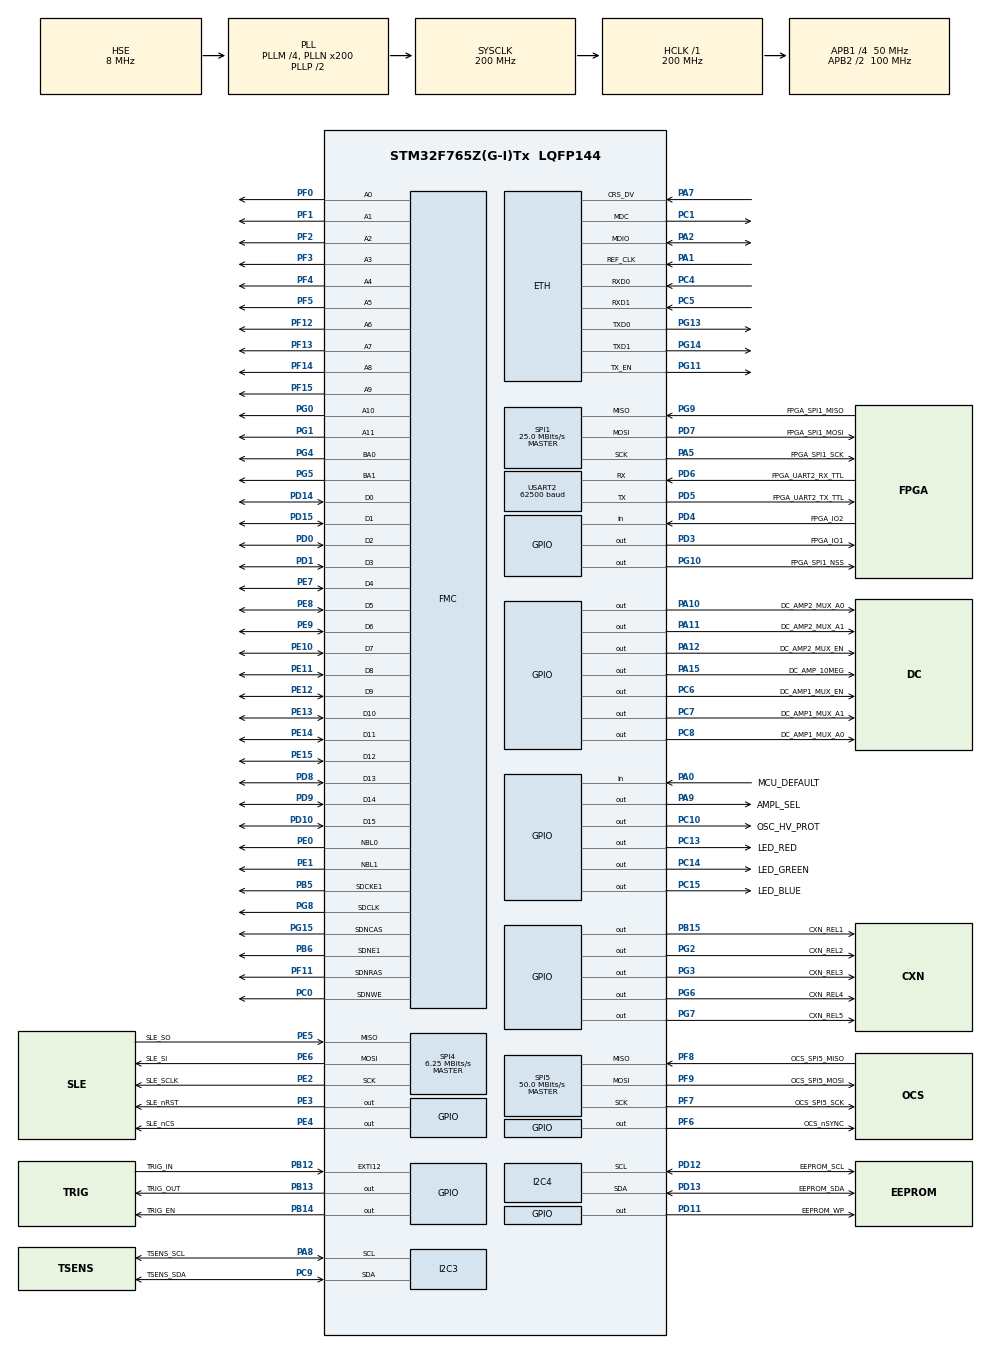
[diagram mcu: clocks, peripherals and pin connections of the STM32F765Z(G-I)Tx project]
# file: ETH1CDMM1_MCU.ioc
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CORTEX_M7.CPU_DCache=Enabled
CORTEX_M7.CPU_ICache=Enabled
ETH.MediaInterface=ETH_MEDIA_INTERFACE_RMII
ETH.PhyAddress=0
FMC.CASLatency1=FMC_SDRAM_CAS_LATENCY_2
FMC.ExitSelfRefreshDelay1=7
FMC.LoadToActiveDelay1=2
FMC.RCDDelay1=2
FMC.RPDelay1=2
FMC.RPDelay2=2
FMC.ReadPipeDelay1=FMC_SDRAM_RPIPE_DELAY_1
FMC.ReadPipeDelay2=FMC_SDRAM_RPIPE_DELAY_1
FMC.RowCycleDelay1=7
FMC.RowCycleDelay2=7
FMC.SDClockPeriod1=FMC_SDRAM_CLOCK_PERIOD_2
FMC.SDClockPeriod2=FMC_SDRAM_CLOCK_PERIOD_2
FMC.SelfRefreshTime1=4
FMC.WriteRecoveryTime1=3
FREERTOS.HEAP_NUMBER=4
FREERTOS.Queues01=QueueTrigger,1,uint8_t,0,Static,QueueTriggerBuffer,QueueTriggerControlBlock
FREERTOS.Tasks01=defaultTask,24,128,StartDefaultTask,Default,NULL,Dynamic,NULL,NULL;LEDTask,8,128,StartLEDTask,Default,NULL,Dynamic,NULL,NULL;TriggerTask,24,128,StartTriggerTask,Default,NULL,Dynamic,NULL,NULL;MeasurTask,25,1024,StartMeasurTask,Default,NULL,Dynamic,NULL,NULL
FREERTOS.configTOTAL_HEAP_SIZE=245760
I2C3.Timing=0x00C0EAFF
I2C4.Timing=0x00C0EAFF
LWIP.CMSIS_VERSION-Enabled=1
LWIP.DEFAULT_THREAD_STACKSIZE=2048
LWIP.GATEWAY_ADDRESS=192.168.000.001
LWIP.IP_ADDRESS=192.168.000.127
LWIP.LWIP_DHCP=0
LWIP.NETMASK_ADDRESS=255.255.255.000
LWIP.SLIPIF_THREAD_STACKSIZE=2048
LWIP.TCPIP_THREAD_STACKSIZE=2048
LWIP.Version=v2.1.2_Cube
Mcu.Family=STM32F7
Mcu.Name=STM32F765Z(G-I)Tx
Mcu.Package=LQFP144
NVIC.ETH_IRQn=true\:5\:0\:false\:false\:true\:true\:false\:true
NVIC.EXTI15_10_IRQn=true\:15\:0\:true\:false\:true\:false\:true\:true
NVIC.PriorityGroup=NVIC_PRIORITYGROUP_4
NVIC.TIM1_UP_TIM10_IRQn=true\:0\:0\:false\:false\:true\:false\:false\:true
NVIC.TimeBase=TIM1_UP_TIM10_IRQn
NVIC.TimeBaseIP=TIM1
PA0/WKUP.GPIO_Label=MCU_DEFAULT
PA0/WKUP.Signal=GPIO_Input
PA1.Mode=RMII
PA1.Signal=ETH_REF_CLK
PA10.GPIO_Label=DC_AMP2_MUX_A0
PA10.Signal=GPIO_Output
PA11.GPIO_Label=DC_AMP2_MUX_A1
PA11.Signal=GPIO_Output
PA12.GPIO_Label=DC_AMP2_MUX_EN
PA12.Signal=GPIO_Output
PA13.Mode=Serial_Wire
PA13.Signal=SYS_JTMS-SWDIO
PA14.Mode=Serial_Wire
PA14.Signal=SYS_JTCK-SWCLK
PA15.GPIO_Label=DC_AMP_10MEG
PA15.Signal=GPIO_Output
PA2.Mode=RMII
PA2.Signal=ETH_MDIO
PA5.GPIO_Label=FPGA_SPI1_SCK
PA5.Mode=Full_Duplex_Master
PA5.Signal=SPI1_SCK
PA7.Mode=RMII
PA7.Signal=ETH_CRS_DV
PA8.GPIO_Label=TSENS_SCL
PA8.Mode=I2C
PA8.Signal=I2C3_SCL
PA9.GPIO_Label=AMPL_SEL
PA9.Signal=GPIO_Output
PB12.GPIO_Label=TRIG_IN
PB12.GPIO_ModeDefaultEXTI=GPIO_MODE_IT_RISING
PB12.Signal=GPXTI12
PB13.GPIO_Label=TRIG_OUT
PB13.Signal=GPIO_Output
PB14.GPIO_Label=TRIG_EN
PB14.PinState=GPIO_PIN_SET
PB14.Signal=GPIO_Output
PB15.GPIO_Label=CXN_REL1
PB15.Signal=GPIO_Output
PB5.Mode=SdramChipSelect2_1
PB5.Signal=FMC_SDCKE1
PB6.Mode=SdramChipSelect2_1
PB6.Signal=FMC_SDNE1
PC0.Signal=FMC_SDNWE
PC1.Mode=RMII
PC1.Signal=ETH_MDC
PC10.GPIO_Label=OSC_HV_PROT
PC10.Signal=GPIO_Output
PC13.GPIO_Label=LED_RED
PC13.PinState=GPIO_PIN_SET
PC13.Signal=GPIO_Output
PC14/OSC32_IN.GPIO_Label=LED_GREEN
PC14/OSC32_IN.PinState=GPIO_PIN_SET
PC14/OSC32_IN.Signal=GPIO_Output
PC15/OSC32_OUT.GPIO_Label=LED_BLUE
PC15/OSC32_OUT.PinState=GPIO_PIN_SET
PC15/OSC32_OUT.Signal=GPIO_Output
PC4.Mode=RMII
PC4.Signal=ETH_RXD0
PC5.Mode=RMII
PC5.Signal=ETH_RXD1
PC6.GPIO_Label=DC_AMP1_MUX_EN
PC6.Signal=GPIO_Output
PC7.GPIO_Label=DC_AMP1_MUX_A1
PC7.Signal=GPIO_Output
PC8.GPIO_Label=DC_AMP1_MUX_A0
PC8.Signal=GPIO_Output
PC9.GPIO_Label=TSENS_SDA
PC9.Mode=I2C
PC9.Signal=I2C3_SDA
PD0.Signal=FMC_D2_DA2
PD1.Signal=FMC_D3_DA3
PD10.Signal=FMC_D15_DA15
PD11.GPIO_Label=EEPROM_WP
PD11.PinState=GPIO_PIN_SET
PD11.Signal=GPIO_Output
PD12.GPIO_Label=EEPROM_SCL
PD12.Mode=I2C
PD12.Signal=I2C4_SCL
PD13.GPIO_Label=EEPROM_SDA
PD13.Mode=I2C
PD13.Signal=I2C4_SDA
PD14.Signal=FMC_D0_DA0
PD15.Signal=FMC_D1_DA1
PD3.GPIO_Label=FPGA_IO1
PD3.Signal=GPIO_Output
PD4.GPIO_Label=FPGA_IO2
PD4.Signal=GPIO_Input
PD5.GPIO_Label=FPGA_UART2_TX_TTL
PD5.Mode=Asynchronous
PD5.Signal=USART2_TX
PD6.GPIO_Label=FPGA_UART2_RX_TTL
PD6.Mode=Asynchronous
PD6.Signal=USART2_RX
PD7.GPIO_Label=FPGA_SPI1_MOSI
PD7.Mode=Full_Duplex_Master
PD7.Signal=SPI1_MOSI
PD8.Signal=FMC_D13_DA13
PD9.Signal=FMC_D14_DA14
PE0.Signal=FMC_NBL0
PE1.Signal=FMC_NBL1
PE10.Signal=FMC_D7_DA7
PE11.Signal=FMC_D8_DA8
PE12.Signal=FMC_D9_DA9
PE13.Signal=FMC_D10_DA10
PE14.Signal=FMC_D11_DA11
PE15.Signal=FMC_D12_DA12
PE2.GPIO_Label=SLE_SCLK
PE2.Mode=Full_Duplex_Master
PE2.Signal=SPI4_SCK
PE3.GPIO_Label=SLE_nRST
PE3.PinState=GPIO_PIN_SET
PE3.Signal=GPIO_Output
PE4.GPIO_Label=SLE_nCS
PE4.PinState=GPIO_PIN_SET
PE4.Signal=GPIO_Output
PE5.GPIO_Label=SLE_SO
PE5.Mode=Full_Duplex_Master
PE5.Signal=SPI4_MISO
PE6.GPIO_Label=SLE_SI
PE6.Mode=Full_Duplex_Master
PE6.Signal=SPI4_MOSI
PE7.Signal=FMC_D4_DA4
PE8.Signal=FMC_D5_DA5
PE9.Signal=FMC_D6_DA6
PF0.Signal=FMC_A0
PF1.Signal=FMC_A1
PF11.Signal=FMC_SDNRAS
PF12.Signal=FMC_A6
PF13.Signal=FMC_A7
PF14.Signal=FMC_A8
PF15.Signal=FMC_A9
PF2.Signal=FMC_A2
PF3.Signal=FMC_A3
PF4.Signal=FMC_A4
PF5.Signal=FMC_A5
PF6.GPIO_Label=OCS_nSYNC
PF6.PinState=GPIO_PIN_SET
PF6.Signal=GPIO_Output
PF7.GPIO_Label=OCS_SPI5_SCK
PF7.Mode=Full_Duplex_Master
PF7.Signal=SPI5_SCK
PF8.GPIO_Label=OCS_SPI5_MISO
PF8.Mode=Full_Duplex_Master
PF8.Signal=SPI5_MISO
PF9.GPIO_Label=OCS_SPI5_MOSI
PF9.Mode=Full_Duplex_Master
PF9.Signal=SPI5_MOSI
PG0.Signal=FMC_A10
PG1.Signal=FMC_A11
PG10.GPIO_Label=FPGA_SPI1_NSS
PG10.PinState=GPIO_PIN_SET
PG10.Signal=GPIO_Output
PG11.Mode=RMII
PG11.Signal=ETH_TX_EN
PG13.Mode=RMII
PG13.Signal=ETH_TXD0
PG14.Mode=RMII
PG14.Signal=ETH_TXD1
PG15.Signal=FMC_SDNCAS
PG2.GPIO_Label=CXN_REL2
PG2.Signal=GPIO_Output
PG3.GPIO_Label=CXN_REL3
PG3.Signal=GPIO_Output
PG4.Signal=FMC_A14_BA0
PG5.Signal=FMC_A15_BA1
PG6.GPIO_Label=CXN_REL4
PG6.Signal=GPIO_Output
PG7.GPIO_Label=CXN_REL5
PG7.Signal=GPIO_Output
PG8.Signal=FMC_SDCLK
PG9.GPIO_Label=FPGA_SPI1_MISO
PG9.Mode=Full_Duplex_Master
PG9.Signal=SPI1_MISO
PH0/OSC_IN.Mode=HSE-External-Oscillator
PH0/OSC_IN.Signal=RCC_OSC_IN
PH1/OSC_OUT.Mode=HSE-External-Oscillator
PH1/OSC_OUT.Signal=RCC_OSC_OUT
ProjectManager.HeapSize=0x200
ProjectManager.StackSize=0x400
ProjectManager.TargetToolchain=STM32CubeIDE
RCC.AHBFreq_Value=200000000
RCC.APB1CLKDivider=RCC_HCLK_DIV4
RCC.APB1Freq_Value=50000000
RCC.APB1TimFreq_Value=100000000
RCC.APB2CLKDivider=RCC_HCLK_DIV2
RCC.APB2Freq_Value=100000000
RCC.APB2TimFreq_Value=200000000
RCC.CortexFreq_Value=200000000
RCC.HCLKFreq_Value=200000000
RCC.HSE_VALUE=8000000
RCC.HSI_VALUE=16000000
RCC.LSE_VALUE=32768
RCC.PLLM=4
RCC.PLLN=200
RCC.PLLSourceVirtual=RCC_PLLSOURCE_HSE
RCC.SYSCLKFreq_VALUE=200000000
RCC.SYSCLKSource=RCC_SYSCLKSOURCE_PLLCLK
RCC.USBFreq_Value=200000000
RCC.VCOOutputFreq_Value=400000000
SH.FMC_A0.0=FMC_A0,12b-sda1
SH.FMC_A1.0=FMC_A1,12b-sda1
SH.FMC_A10.0=FMC_A10,12b-sda1
SH.FMC_A11.0=FMC_A11,12b-sda1
SH.FMC_A14_BA0.0=FMC_BA0,FourSdramBanks1
SH.FMC_A15_BA1.0=FMC_BA1,FourSdramBanks1
SH.FMC_A2.0=FMC_A2,12b-sda1
SH.FMC_A3.0=FMC_A3,12b-sda1
SH.FMC_A4.0=FMC_A4,12b-sda1
SH.FMC_A5.0=FMC_A5,12b-sda1
SH.FMC_A6.0=FMC_A6,12b-sda1
SH.FMC_A7.0=FMC_A7,12b-sda1
SH.FMC_A8.0=FMC_A8,12b-sda1
SH.FMC_A9.0=FMC_A9,12b-sda1
SH.FMC_D0_DA0.0=FMC_D0,sd-16b-d1
SH.FMC_D10_DA10.0=FMC_D10,sd-16b-d1
SH.FMC_D11_DA11.0=FMC_D11,sd-16b-d1
SH.FMC_D12_DA12.0=FMC_D12,sd-16b-d1
SH.FMC_D13_DA13.0=FMC_D13,sd-16b-d1
SH.FMC_D14_DA14.0=FMC_D14,sd-16b-d1
SH.FMC_D15_DA15.0=FMC_D15,sd-16b-d1
SH.FMC_D1_DA1.0=FMC_D1,sd-16b-d1
SH.FMC_D2_DA2.0=FMC_D2,sd-16b-d1
SH.FMC_D3_DA3.0=FMC_D3,sd-16b-d1
SH.FMC_D4_DA4.0=FMC_D4,sd-16b-d1
SH.FMC_D5_DA5.0=FMC_D5,sd-16b-d1
SH.FMC_D6_DA6.0=FMC_D6,sd-16b-d1
SH.FMC_D7_DA7.0=FMC_D7,sd-16b-d1
SH.FMC_D8_DA8.0=FMC_D8,sd-16b-d1
SH.FMC_D9_DA9.0=FMC_D9,sd-16b-d1
SH.FMC_NBL0.0=FMC_NBL0,Sd2ByteEnable1
SH.FMC_NBL1.0=FMC_NBL1,Sd2ByteEnable1
SH.FMC_SDCLK.0=FMC_SDCLK,12b-sda1
SH.FMC_SDNCAS.0=FMC_SDNCAS,12b-sda1
SH.FMC_SDNRAS.0=FMC_SDNRAS,12b-sda1
SH.FMC_SDNWE.0=FMC_SDNWE,12b-sda1
SPI1.BaudRatePrescaler=SPI_BAUDRATEPRESCALER_4
SPI1.CalculateBaudRate=25.0 MBits/s
SPI1.DataSize=SPI_DATASIZE_8BIT
SPI1.Direction=SPI_DIRECTION_2LINES
SPI1.Mode=SPI_MODE_MASTER
SPI1.VirtualType=VM_MASTER
SPI4.BaudRatePrescaler=SPI_BAUDRATEPRESCALER_16
SPI4.CLKPhase=SPI_PHASE_2EDGE
SPI4.CalculateBaudRate=6.25 MBits/s
SPI4.DataSize=SPI_DATASIZE_8BIT
SPI4.Direction=SPI_DIRECTION_2LINES
SPI4.Mode=SPI_MODE_MASTER
SPI4.VirtualType=VM_MASTER
SPI5.BaudRatePrescaler=SPI_BAUDRATEPRESCALER_2
SPI5.CalculateBaudRate=50.0 MBits/s
SPI5.Direction=SPI_DIRECTION_2LINES
SPI5.Mode=SPI_MODE_MASTER
SPI5.VirtualType=VM_MASTER
USART2.BaudRate=62500
USART2.VirtualMode-Asynchronous=VM_ASYNC
VP_FREERTOS_VS_CMSIS_V2.Mode=CMSIS_V2
VP_LWIP_VS_Enabled.Mode=Enabled
VP_SYS_VS_tim1.Mode=TIM1
board=custom

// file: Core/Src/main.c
/* USER CODE BEGIN Header */
/**
  ******************************************************************************
  * @file           : main.c
  * @brief          : Main program body
  ******************************************************************************
  * @attention
  *
  * <h2><center>&copy; Copyright (c) 2020 STMicroelectronics.
  * All rights reserved.</center></h2>
  *
  * This software component is licensed by ST under BSD 3-Clause license,
  * the "License"; You may not use this file except in compliance with the
  * License. You may obtain a copy of the License at:
  *                        opensource.org/licenses/BSD-3-Clause
  *
  ******************************************************************************
  */
/* USER CODE END Header */
#include "main.h"
#include "cmsis_os.h"
#include "lwip.h"

/* USER CODE BEGIN Includes */
#include "bsp.h"
#include "bsp_init.h"
#include "scpi_server.h"
/* USER CODE END Includes */

typedef StaticQueue_t osStaticMessageQDef_t;

/* USER CODE BEGIN PD */
static void BSP_SDRAM_Initialization(SDRAM_HandleTypeDef *hsdram, FMC_SDRAM_CommandTypeDef *Command);
FMC_SDRAM_CommandTypeDef command;
/* USER CODE END PD */

I2C_HandleTypeDef hi2c3;
I2C_HandleTypeDef hi2c4;

SPI_HandleTypeDef hspi1;
SPI_HandleTypeDef hspi4;
SPI_HandleTypeDef hspi5;

UART_HandleTypeDef huart2;

SDRAM_HandleTypeDef hsdram1;

/* Definitions for defaultTask */
osThreadId_t defaultTaskHandle;
const osThreadAttr_t defaultTask_attributes = {
  .name = "defaultTask",
  .priority = (osPriority_t) osPriorityNormal,
  .stack_size = 128 * 4
};
/* Definitions for LEDTask */
osThreadId_t LEDTaskHandle;
const osThreadAttr_t LEDTask_attributes = {
  .name = "LEDTask",
  .priority = (osPriority_t) osPriorityLow,
  .stack_size = 128 * 4
};
/* Definitions for TriggerTask */
osThreadId_t TriggerTaskHandle;
const osThreadAttr_t TriggerTask_attributes = {
  .name = "TriggerTask",
  .priority = (osPriority_t) osPriorityNormal,
  .stack_size = 128 * 4
};
/* Definitions for MeasurTask */
osThreadId_t MeasurTaskHandle;
const osThreadAttr_t MeasurTask_attributes = {
  .name = "MeasurTask",
  .priority = (osPriority_t) osPriorityNormal1,
  .stack_size = 1024 * 4
};
/* Definitions for QueueTrigger */
osMessageQueueId_t QueueTriggerHandle;
uint8_t QueueTriggerBuffer[ 1 * sizeof( uint8_t ) ];
osStaticMessageQDef_t QueueTriggerControlBlock;
const osMessageQueueAttr_t QueueTrigger_attributes = {
  .name = "QueueTrigger",
  .cb_mem = &QueueTriggerControlBlock,
  .cb_size = sizeof(QueueTriggerControlBlock),
  .mq_mem = &QueueTriggerBuffer,
  .mq_size = sizeof(QueueTriggerBuffer)
};
/* USER CODE BEGIN PV */

uint8_t rx_data[6] = {0x00};
uint8_t it_array_mul[10]={1, 1, 1, 1, 2, 5, 10, 0};
double it_array_refcor[3]={1, 1.01582, 1};
uint32_t count_fail= 0;
uint8_t new_data = 0;
struct cfg_struct dmm;

/* USER CODE END PV */

void SystemClock_Config(void);
static void MX_GPIO_Init(void);
static void MX_I2C4_Init(void);
static void MX_FMC_Init(void);
static void MX_I2C3_Init(void);
static void MX_SPI1_Init(void);
static void MX_SPI5_Init(void);
static void MX_USART2_UART_Init(void);
static void MX_SPI4_Init(void);
void StartDefaultTask(void *argument);
void StartLEDTask(void *argument);
void StartTriggerTask(void *argument);
void StartMeasurTask(void *argument);

/* USER CODE BEGIN 0 */
void DMM_Init();
/* USER CODE END 0 */

int main(void)
{

  /* Enable I-Cache---------------------------------------------------------*/
  SCB_EnableICache();

  /* Enable D-Cache---------------------------------------------------------*/
  SCB_EnableDCache();

  /* MCU Configuration--------------------------------------------------------*/

  /* Reset of all peripherals, Initializes the Flash interface and the Systick. */
  HAL_Init();

  /* Configure the system clock */
  SystemClock_Config();

  /* Initialize all configured peripherals */
  MX_GPIO_Init();
  MX_I2C4_Init();
  MX_FMC_Init();
  MX_I2C3_Init();
  MX_SPI1_Init();
  MX_SPI5_Init();
  MX_USART2_UART_Init();
  MX_SPI4_Init();
  /* USER CODE BEGIN 2 */
  BSP_Init();
  MX_LWIP_Init();
  DMM_Init();
  /* USER CODE END 2 */

  /* Init scheduler */
  osKernelInitialize();

  /* Create the queue(s) */
  /* creation of QueueTrigger */
  QueueTriggerHandle = osMessageQueueNew (1, sizeof(uint8_t), &QueueTrigger_attributes);

  /* Create the thread(s) */
  /* creation of defaultTask */
  //defaultTaskHandle = osThreadNew(StartDefaultTask, NULL, &defaultTask_attributes);

  /* creation of LEDTask */
  //LEDTaskHandle = osThreadNew(StartLEDTask, NULL, &LEDTask_attributes);

  /* creation of TriggerTask */
  TriggerTaskHandle = osThreadNew(StartTriggerTask, NULL, &TriggerTask_attributes);

  /* creation of MeasurTask */
  MeasurTaskHandle = osThreadNew(StartMeasurTask, NULL, &MeasurTask_attributes);

  /* USER CODE BEGIN RTOS_THREADS */
  scpi_server_init();

  osThreadSuspend(TriggerTaskHandle);

  /* USER CODE END RTOS_THREADS */

  /* Start scheduler */
  osKernelStart();

  /* We should never get here as control is now taken by the scheduler */
  /* Infinite loop */
  while (1)
  {

  }
}

void SystemClock_Config(void)
{
  RCC_OscInitTypeDef RCC_OscInitStruct = {0};
  RCC_ClkInitTypeDef RCC_ClkInitStruct = {0};
  RCC_PeriphCLKInitTypeDef PeriphClkInitStruct = {0};

  /** Configure the main internal regulator output voltage
  */
  __HAL_RCC_PWR_CLK_ENABLE();
  __HAL_PWR_VOLTAGESCALING_CONFIG(PWR_REGULATOR_VOLTAGE_SCALE1);
  /** Initializes the RCC Oscillators according to the specified parameters
  * in the RCC_OscInitTypeDef structure.
  */
  RCC_OscInitStruct.OscillatorType = RCC_OSCILLATORTYPE_HSE;
  RCC_OscInitStruct.HSEState = RCC_HSE_ON;
  RCC_OscInitStruct.PLL.PLLState = RCC_PLL_ON;
  RCC_OscInitStruct.PLL.PLLSource = RCC_PLLSOURCE_HSE;
  RCC_OscInitStruct.PLL.PLLM = 4;
  RCC_OscInitStruct.PLL.PLLN = 200;
  RCC_OscInitStruct.PLL.PLLP = RCC_PLLP_DIV2;
  RCC_OscInitStruct.PLL.PLLQ = 2;
  if (HAL_RCC_OscConfig(&RCC_OscInitStruct) != HAL_OK)
  {
    Error_Handler();
  }
  /** Activate the Over-Drive mode
  */
  if (HAL_PWREx_EnableOverDrive() != HAL_OK)
  {
    Error_Handler();
  }
  /** Initializes the CPU, AHB and APB buses clocks
  */
  RCC_ClkInitStruct.ClockType = RCC_CLOCKTYPE_HCLK|RCC_CLOCKTYPE_SYSCLK
                              |RCC_CLOCKTYPE_PCLK1|RCC_CLOCKTYPE_PCLK2;
  RCC_ClkInitStruct.SYSCLKSource = RCC_SYSCLKSOURCE_PLLCLK;
  RCC_ClkInitStruct.AHBCLKDivider = RCC_SYSCLK_DIV1;
  RCC_ClkInitStruct.APB1CLKDivider = RCC_HCLK_DIV4;
  RCC_ClkInitStruct.APB2CLKDivider = RCC_HCLK_DIV2;

  if (HAL_RCC_ClockConfig(&RCC_ClkInitStruct, FLASH_LATENCY_6) != HAL_OK)
  {
    Error_Handler();
  }
  PeriphClkInitStruct.PeriphClockSelection = RCC_PERIPHCLK_USART2|RCC_PERIPHCLK_I2C3
                              |RCC_PERIPHCLK_I2C4;
  PeriphClkInitStruct.Usart2ClockSelection = RCC_USART2CLKSOURCE_PCLK1;
  PeriphClkInitStruct.I2c3ClockSelection = RCC_I2C3CLKSOURCE_PCLK1;
  PeriphClkInitStruct.I2c4ClockSelection = RCC_I2C4CLKSOURCE_PCLK1;
  if (HAL_RCCEx_PeriphCLKConfig(&PeriphClkInitStruct) != HAL_OK)
  {
    Error_Handler();
  }
}

static void MX_I2C3_Init(void)
{

  hi2c3.Instance = I2C3;
  hi2c3.Init.Timing = 0x00C0EAFF;
  hi2c3.Init.OwnAddress1 = 0;
  hi2c3.Init.AddressingMode = I2C_ADDRESSINGMODE_7BIT;
  hi2c3.Init.DualAddressMode = I2C_DUALADDRESS_DISABLE;
  hi2c3.Init.OwnAddress2 = 0;
  hi2c3.Init.OwnAddress2Masks = I2C_OA2_NOMASK;
  hi2c3.Init.GeneralCallMode = I2C_GENERALCALL_DISABLE;
  hi2c3.Init.NoStretchMode = I2C_NOSTRETCH_DISABLE;
  if (HAL_I2C_Init(&hi2c3) != HAL_OK)
  {
    Error_Handler();
  }
  /** Configure Analogue filter
  */
  if (HAL_I2CEx_ConfigAnalogFilter(&hi2c3, I2C_ANALOGFILTER_ENABLE) != HAL_OK)
  {
    Error_Handler();
  }
  /** Configure Digital filter
  */
  if (HAL_I2CEx_ConfigDigitalFilter(&hi2c3, 0) != HAL_OK)
  {
    Error_Handler();
  }

}

static void MX_I2C4_Init(void)
{

  hi2c4.Instance = I2C4;
  hi2c4.Init.Timing = 0x00C0EAFF;
  hi2c4.Init.OwnAddress1 = 0;
  hi2c4.Init.AddressingMode = I2C_ADDRESSINGMODE_7BIT;
  hi2c4.Init.DualAddressMode = I2C_DUALADDRESS_DISABLE;
  hi2c4.Init.OwnAddress2 = 0;
  hi2c4.Init.OwnAddress2Masks = I2C_OA2_NOMASK;
  hi2c4.Init.GeneralCallMode = I2C_GENERALCALL_DISABLE;
  hi2c4.Init.NoStretchMode = I2C_NOSTRETCH_DISABLE;
  if (HAL_I2C_Init(&hi2c4) != HAL_OK)
  {
    Error_Handler();
  }
  /** Configure Analogue filter
  */
  if (HAL_I2CEx_ConfigAnalogFilter(&hi2c4, I2C_ANALOGFILTER_ENABLE) != HAL_OK)
  {
    Error_Handler();
  }
  /** Configure Digital filter
  */
  if (HAL_I2CEx_ConfigDigitalFilter(&hi2c4, 0) != HAL_OK)
  {
    Error_Handler();
  }

}

static void MX_SPI1_Init(void)
{

  /* SPI1 parameter configuration*/
  hspi1.Instance = SPI1;
  hspi1.Init.Mode = SPI_MODE_MASTER;
  hspi1.Init.Direction = SPI_DIRECTION_2LINES;
  hspi1.Init.DataSize = SPI_DATASIZE_8BIT;
  hspi1.Init.CLKPolarity = SPI_POLARITY_LOW;
  hspi1.Init.CLKPhase = SPI_PHASE_1EDGE;
  hspi1.Init.NSS = SPI_NSS_SOFT;
  hspi1.Init.BaudRatePrescaler = SPI_BAUDRATEPRESCALER_4;
  hspi1.Init.FirstBit = SPI_FIRSTBIT_MSB;
  hspi1.Init.TIMode = SPI_TIMODE_DISABLE;
  hspi1.Init.CRCCalculation = SPI_CRCCALCULATION_DISABLE;
  hspi1.Init.CRCPolynomial = 7;
  hspi1.Init.CRCLength = SPI_CRC_LENGTH_DATASIZE;
  hspi1.Init.NSSPMode = SPI_NSS_PULSE_ENABLE;
  if (HAL_SPI_Init(&hspi1) != HAL_OK)
  {
    Error_Handler();
  }

}

static void MX_SPI4_Init(void)
{

  /* SPI4 parameter configuration*/
  hspi4.Instance = SPI4;
  hspi4.Init.Mode = SPI_MODE_MASTER;
  hspi4.Init.Direction = SPI_DIRECTION_2LINES;
  hspi4.Init.DataSize = SPI_DATASIZE_8BIT;
  hspi4.Init.CLKPolarity = SPI_POLARITY_LOW;
  hspi4.Init.CLKPhase = SPI_PHASE_2EDGE;
  hspi4.Init.NSS = SPI_NSS_SOFT;
  hspi4.Init.BaudRatePrescaler = SPI_BAUDRATEPRESCALER_16;
  hspi4.Init.FirstBit = SPI_FIRSTBIT_MSB;
  hspi4.Init.TIMode = SPI_TIMODE_DISABLE;
  hspi4.Init.CRCCalculation = SPI_CRCCALCULATION_DISABLE;
  hspi4.Init.CRCPolynomial = 7;
  hspi4.Init.CRCLength = SPI_CRC_LENGTH_DATASIZE;
  hspi4.Init.NSSPMode = SPI_NSS_PULSE_DISABLE;
  if (HAL_SPI_Init(&hspi4) != HAL_OK)
  {
    Error_Handler();
  }

}

static void MX_SPI5_Init(void)
{

  /* SPI5 parameter configuration*/
  hspi5.Instance = SPI5;
  hspi5.Init.Mode = SPI_MODE_MASTER;
  hspi5.Init.Direction = SPI_DIRECTION_2LINES;
  hspi5.Init.DataSize = SPI_DATASIZE_4BIT;
  hspi5.Init.CLKPolarity = SPI_POLARITY_LOW;
  hspi5.Init.CLKPhase = SPI_PHASE_1EDGE;
  hspi5.Init.NSS = SPI_NSS_SOFT;
  hspi5.Init.BaudRatePrescaler = SPI_BAUDRATEPRESCALER_2;
  hspi5.Init.FirstBit = SPI_FIRSTBIT_MSB;
  hspi5.Init.TIMode = SPI_TIMODE_DISABLE;
  hspi5.Init.CRCCalculation = SPI_CRCCALCULATION_DISABLE;
  hspi5.Init.CRCPolynomial = 7;
  hspi5.Init.CRCLength = SPI_CRC_LENGTH_DATASIZE;
  hspi5.Init.NSSPMode = SPI_NSS_PULSE_ENABLE;
  if (HAL_SPI_Init(&hspi5) != HAL_OK)
  {
    Error_Handler();
  }

}

static void MX_USART2_UART_Init(void)
{

  huart2.Instance = USART2;
  huart2.Init.BaudRate = 62500;
  huart2.Init.WordLength = UART_WORDLENGTH_8B;
  huart2.Init.StopBits = UART_STOPBITS_1;
  huart2.Init.Parity = UART_PARITY_NONE;
  huart2.Init.Mode = UART_MODE_TX_RX;
  huart2.Init.HwFlowCtl = UART_HWCONTROL_NONE;
  huart2.Init.OverSampling = UART_OVERSAMPLING_16;
  huart2.Init.OneBitSampling = UART_ONE_BIT_SAMPLE_DISABLE;
  huart2.AdvancedInit.AdvFeatureInit = UART_ADVFEATURE_NO_INIT;
  if (HAL_UART_Init(&huart2) != HAL_OK)
  {
    Error_Handler();
  }

}

/* FMC initialization function */
static void MX_FMC_Init(void)
{

  FMC_SDRAM_TimingTypeDef SdramTiming = {0};

  /** Perform the SDRAM1 memory initialization sequence
  */
  hsdram1.Instance = FMC_SDRAM_DEVICE;
  /* hsdram1.Init */
  hsdram1.Init.SDBank = FMC_SDRAM_BANK2;
  hsdram1.Init.ColumnBitsNumber = FMC_SDRAM_COLUMN_BITS_NUM_8;
  hsdram1.Init.RowBitsNumber = FMC_SDRAM_ROW_BITS_NUM_12;
  hsdram1.Init.MemoryDataWidth = FMC_SDRAM_MEM_BUS_WIDTH_16;
  hsdram1.Init.InternalBankNumber = FMC_SDRAM_INTERN_BANKS_NUM_4;
  hsdram1.Init.CASLatency = FMC_SDRAM_CAS_LATENCY_2;
  hsdram1.Init.WriteProtection = FMC_SDRAM_WRITE_PROTECTION_DISABLE;
  hsdram1.Init.SDClockPeriod = FMC_SDRAM_CLOCK_PERIOD_2;
  hsdram1.Init.ReadBurst = FMC_SDRAM_RBURST_DISABLE;
  hsdram1.Init.ReadPipeDelay = FMC_SDRAM_RPIPE_DELAY_1;
  /* SdramTiming */
  SdramTiming.LoadToActiveDelay = 2;
  SdramTiming.ExitSelfRefreshDelay = 7;
  SdramTiming.SelfRefreshTime = 4;
  SdramTiming.RowCycleDelay = 7;
  SdramTiming.WriteRecoveryTime = 3;
  SdramTiming.RPDelay = 2;
  SdramTiming.RCDDelay = 2;

  if (HAL_SDRAM_Init(&hsdram1, &SdramTiming) != HAL_OK)
  {
    Error_Handler( );
  }

  /* USER CODE BEGIN FMC_Init 2 */
  BSP_SDRAM_Initialization(&hsdram1, &command);
  /* USER CODE END FMC_Init 2 */
}

static void MX_GPIO_Init(void)
{
  GPIO_InitTypeDef GPIO_InitStruct = {0};

  /* GPIO Ports Clock Enable */
  __HAL_RCC_GPIOE_CLK_ENABLE();
  __HAL_RCC_GPIOC_CLK_ENABLE();
  __HAL_RCC_GPIOF_CLK_ENABLE();
  __HAL_RCC_GPIOH_CLK_ENABLE();
  __HAL_RCC_GPIOA_CLK_ENABLE();
  __HAL_RCC_GPIOG_CLK_ENABLE();
  __HAL_RCC_GPIOB_CLK_ENABLE();
  __HAL_RCC_GPIOD_CLK_ENABLE();

  /*Configure GPIO pin Output Level */
  HAL_GPIO_WritePin(GPIOE, SLE_nRST_Pin|SLE_nCS_Pin, GPIO_PIN_SET);

  /*Configure GPIO pin Output Level */
  HAL_GPIO_WritePin(GPIOC, LED_RED_Pin|LED_GREEN_Pin|LED_BLUE_Pin, GPIO_PIN_SET);

  /*Configure GPIO pin Output Level */
  HAL_GPIO_WritePin(OCS_nSYNC_GPIO_Port, OCS_nSYNC_Pin, GPIO_PIN_SET);

  /*Configure GPIO pin Output Level */
  HAL_GPIO_WritePin(GPIOB, TRIG_OUT_Pin|CXN_REL1_Pin, GPIO_PIN_RESET);

  /*Configure GPIO pin Output Level */
  HAL_GPIO_WritePin(TRIG_EN_GPIO_Port, TRIG_EN_Pin, GPIO_PIN_SET);

  /*Configure GPIO pin Output Level */
  HAL_GPIO_WritePin(EEPROM_WP_GPIO_Port, EEPROM_WP_Pin, GPIO_PIN_SET);

  /*Configure GPIO pin Output Level */
  HAL_GPIO_WritePin(GPIOG, CXN_REL2_Pin|CXN_REL3_Pin|CXN_REL4_Pin|CXN_REL5_Pin, GPIO_PIN_RESET);

  /*Configure GPIO pin Output Level */
  HAL_GPIO_WritePin(GPIOC, DC_AMP1_MUX_EN_Pin|DC_AMP1_MUX_A1_Pin|DC_AMP1_MUX_A0_Pin|OSC_HV_PROT_Pin, GPIO_PIN_RESET);

  /*Configure GPIO pin Output Level */
  HAL_GPIO_WritePin(GPIOA, AMPL_SEL_Pin|DC_AMP2_MUX_A0_Pin|DC_AMP2_MUX_A1_Pin|DC_AMP2_MUX_EN_Pin
                          |DC_AMP_10MEG_Pin, GPIO_PIN_RESET);

  /*Configure GPIO pin Output Level */
  HAL_GPIO_WritePin(FPGA_IO1_GPIO_Port, FPGA_IO1_Pin, GPIO_PIN_RESET);

  /*Configure GPIO pin Output Level */
  HAL_GPIO_WritePin(FPGA_SPI1_NSS_GPIO_Port, FPGA_SPI1_NSS_Pin, GPIO_PIN_SET);

  /*Configure GPIO pins : SLE_nRST_Pin SLE_nCS_Pin */
  GPIO_InitStruct.Pin = SLE_nRST_Pin|SLE_nCS_Pin;
  GPIO_InitStruct.Mode = GPIO_MODE_OUTPUT_PP;
  GPIO_InitStruct.Pull = GPIO_NOPULL;
  GPIO_InitStruct.Speed = GPIO_SPEED_FREQ_LOW;
  HAL_GPIO_Init(GPIOE, &GPIO_InitStruct);

  /*Configure GPIO pins : LED_RED_Pin LED_GREEN_Pin LED_BLUE_Pin DC_AMP1_MUX_EN_Pin
                           DC_AMP1_MUX_A1_Pin DC_AMP1_MUX_A0_Pin OSC_HV_PROT_Pin */
  GPIO_InitStruct.Pin = LED_RED_Pin|LED_GREEN_Pin|LED_BLUE_Pin|DC_AMP1_MUX_EN_Pin
                          |DC_AMP1_MUX_A1_Pin|DC_AMP1_MUX_A0_Pin|OSC_HV_PROT_Pin;
  GPIO_InitStruct.Mode = GPIO_MODE_OUTPUT_PP;
  GPIO_InitStruct.Pull = GPIO_NOPULL;
  GPIO_InitStruct.Speed = GPIO_SPEED_FREQ_LOW;
  HAL_GPIO_Init(GPIOC, &GPIO_InitStruct);

  /*Configure GPIO pin : OCS_nSYNC_Pin */
  GPIO_InitStruct.Pin = OCS_nSYNC_Pin;
  GPIO_InitStruct.Mode = GPIO_MODE_OUTPUT_PP;
  GPIO_InitStruct.Pull = GPIO_NOPULL;
  GPIO_InitStruct.Speed = GPIO_SPEED_FREQ_LOW;
  HAL_GPIO_Init(OCS_nSYNC_GPIO_Port, &GPIO_InitStruct);

  /*Configure GPIO pin : MCU_DEFAULT_Pin */
  GPIO_InitStruct.Pin = MCU_DEFAULT_Pin;
  GPIO_InitStruct.Mode = GPIO_MODE_INPUT;
  GPIO_InitStruct.Pull = GPIO_NOPULL;
  HAL_GPIO_Init(MCU_DEFAULT_GPIO_Port, &GPIO_InitStruct);

  /*Configure GPIO pin : TRIG_IN_Pin */
  GPIO_InitStruct.Pin = TRIG_IN_Pin;
  GPIO_InitStruct.Mode = GPIO_MODE_IT_RISING;
  GPIO_InitStruct.Pull = GPIO_NOPULL;
  HAL_GPIO_Init(TRIG_IN_GPIO_Port, &GPIO_InitStruct);

  /*Configure GPIO pins : TRIG_OUT_Pin TRIG_EN_Pin CXN_REL1_Pin */
  GPIO_InitStruct.Pin = TRIG_OUT_Pin|TRIG_EN_Pin|CXN_REL1_Pin;
  GPIO_InitStruct.Mode = GPIO_MODE_OUTPUT_PP;
  GPIO_InitStruct.Pull = GPIO_NOPULL;
  GPIO_InitStruct.Speed = GPIO_SPEED_FREQ_LOW;
  HAL_GPIO_Init(GPIOB, &GPIO_InitStruct);

  /*Configure GPIO pins : EEPROM_WP_Pin FPGA_IO1_Pin */
  GPIO_InitStruct.Pin = EEPROM_WP_Pin|FPGA_IO1_Pin;
  GPIO_InitStruct.Mode = GPIO_MODE_OUTPUT_PP;
  GPIO_InitStruct.Pull = GPIO_NOPULL;
  GPIO_InitStruct.Speed = GPIO_SPEED_FREQ_LOW;
  HAL_GPIO_Init(GPIOD, &GPIO_InitStruct);

  /*Configure GPIO pins : CXN_REL2_Pin CXN_REL3_Pin CXN_REL4_Pin CXN_REL5_Pin
                           FPGA_SPI1_NSS_Pin */
  GPIO_InitStruct.Pin = CXN_REL2_Pin|CXN_REL3_Pin|CXN_REL4_Pin|CXN_REL5_Pin
                          |FPGA_SPI1_NSS_Pin;
  GPIO_InitStruct.Mode = GPIO_MODE_OUTPUT_PP;
  GPIO_InitStruct.Pull = GPIO_NOPULL;
  GPIO_InitStruct.Speed = GPIO_SPEED_FREQ_LOW;
  HAL_GPIO_Init(GPIOG, &GPIO_InitStruct);

  /*Configure GPIO pins : AMPL_SEL_Pin DC_AMP2_MUX_A0_Pin DC_AMP2_MUX_A1_Pin DC_AMP2_MUX_EN_Pin
                           DC_AMP_10MEG_Pin */
  GPIO_InitStruct.Pin = AMPL_SEL_Pin|DC_AMP2_MUX_A0_Pin|DC_AMP2_MUX_A1_Pin|DC_AMP2_MUX_EN_Pin
                          |DC_AMP_10MEG_Pin;
  GPIO_InitStruct.Mode = GPIO_MODE_OUTPUT_PP;
  GPIO_InitStruct.Pull = GPIO_NOPULL;
  GPIO_InitStruct.Speed = GPIO_SPEED_FREQ_LOW;
  HAL_GPIO_Init(GPIOA, &GPIO_InitStruct);

  /*Configure GPIO pin : FPGA_IO2_Pin */
  GPIO_InitStruct.Pin = FPGA_IO2_Pin;
  GPIO_InitStruct.Mode = GPIO_MODE_INPUT;
  GPIO_InitStruct.Pull = GPIO_NOPULL;
  HAL_GPIO_Init(FPGA_IO2_GPIO_Port, &GPIO_InitStruct);

  /* EXTI interrupt init*/
  HAL_NVIC_SetPriority(EXTI15_10_IRQn, 15, 0);
  HAL_NVIC_EnableIRQ(EXTI15_10_IRQn);

}

/* USER CODE BEGIN 4 */

/**
  * @brief  Perform the SDRAM exernal memory inialization sequence
  * @param  hsdram: SDRAM handle
  * @param  Command: Pointer to SDRAM command structure
  * @retval None
  */
static void BSP_SDRAM_Initialization(SDRAM_HandleTypeDef *hsdram, FMC_SDRAM_CommandTypeDef *Command)
{
  __IO uint32_t tmpmrd =0;
  /* Step 3:  Configure a clock configuration enable command */
  Command->CommandMode 			 = FMC_SDRAM_CMD_CLK_ENABLE;
  Command->CommandTarget 		 = FMC_SDRAM_CMD_TARGET_BANK2;
  Command->AutoRefreshNumber 	 = 1;
  Command->ModeRegisterDefinition = 0;

  /* Send the command */
  HAL_SDRAM_SendCommand(hsdram, Command, 0x1000);

  /* Step 4: Insert 100 ms delay */
  HAL_Delay(100);

  /* Step 5: Configure a PALL (precharge all) command */
  Command->CommandMode 			 = FMC_SDRAM_CMD_PALL;
  Command->CommandTarget 	     = FMC_SDRAM_CMD_TARGET_BANK2;
  Command->AutoRefreshNumber 	 = 1;
  Command->ModeRegisterDefinition = 0;

  /* Send the command */
  HAL_SDRAM_SendCommand(hsdram, Command, 0x1000);

  /* Step 6 : Configure a Auto-Refresh command */
  Command->CommandMode 			 = FMC_SDRAM_CMD_AUTOREFRESH_MODE;
  Command->CommandTarget 		 = FMC_SDRAM_CMD_TARGET_BANK2;
  Command->AutoRefreshNumber 	 = 4;
  Command->ModeRegisterDefinition = 0;

  /* Send the command */
  HAL_SDRAM_SendCommand(hsdram, Command, 0x1000);

  /* Step 7: Program the external memory mode register */
  tmpmrd = (uint32_t)SDRAM_MODEREG_BURST_LENGTH_2          |
                     SDRAM_MODEREG_BURST_TYPE_SEQUENTIAL   |
                     SDRAM_MODEREG_CAS_LATENCY_3           |
                     SDRAM_MODEREG_OPERATING_MODE_STANDARD |
                     SDRAM_MODEREG_WRITEBURST_MODE_SINGLE;

  Command->CommandMode = FMC_SDRAM_CMD_LOAD_MODE;
  Command->CommandTarget 		 = FMC_SDRAM_CMD_TARGET_BANK2;
  Command->AutoRefreshNumber 	 = 1;
  Command->ModeRegisterDefinition = tmpmrd;

  /* Send the command */
  HAL_SDRAM_SendCommand(hsdram, Command, 0x1000);

  /* Step 8: Set the refresh rate counter */
  /* (15.62 us x Freq) - 20 */
  /* Set the device refresh counter */
  HAL_SDRAM_ProgramRefreshRate(hsdram, REFRESH_COUNT);
}

void DMM_Init()
{

	 dmm.calibration.structure.adc_step = CAL_PREDEF_STEP;
	 dmm.calibration.structure.adc_z_offset = CAL_PREDEF_NZO;
	 dmm.calibration.structure.v_1V_offset = CAL_PREDEF_1VO;
	 dmm.calibration.structure.v_1V_gain = CAL_PREDEF_1VG;
	 dmm.calibration.structure.v_10V_offset = CAL_PREDEF_10VO;
	 dmm.calibration.structure.v_10V_gain = CAL_PREDEF_10VG;
	 dmm.calibration.structure.v_100V_offset = CAL_PREDEF_100VO;
	 dmm.calibration.structure.v_100V_gain = CAL_PREDEF_100VG;

	 dmm.adc_cf[0] = 1.000145;
	 dmm.adc_cf[1] = 1.000060;
	 dmm.adc_cf[2] = 1.000015;
	 dmm.adc_cf[3] = 1.0;
	 dmm.adc_cf[4] = 1.0;
	 dmm.adc_cf[5] = 1.0;
	 dmm.adc_cf[6] = 1.0;

	 dmm.adc_raw[0] = 1;
	 dmm.adc_raw[1] = 2;
	 dmm.adc_raw[2] = 5;
	 dmm.adc_raw[3] = 10;
	 dmm.adc_raw[4] = 10;
	 dmm.adc_raw[5] = 10;
	 dmm.adc_raw[6] = 10;

	 dmm.adc_nplc[0] = 1;
	 dmm.adc_nplc[1] = 2;
	 dmm.adc_nplc[2] = 5;
	 dmm.adc_nplc[3] = 10;
	 dmm.adc_nplc[4] = 20;
	 dmm.adc_nplc[5] = 50;
	 dmm.adc_nplc[6] = 100;

	 dmm.nplc = 10;
	 dmm.range = 10;
	 dmm.range_index = 2;
	 dmm.nplc_index = 3;
	 dmm.samples = 1;
	 dmm.zero_val = 0.0;
	 dmm.zero_done = 0;
	 dmm.zero_status = ZERO_ON;

	//meas_path(dmm.range, NORM_MEAS);

	HAL_GPIO_WritePin(FPGA_IO1_GPIO_Port, FPGA_IO1_Pin, 1);

}

/* USER CODE END 4 */

void StartDefaultTask(void *argument)
{
  /* init code for LWIP */
  MX_LWIP_Init();
  /* USER CODE BEGIN 5 */

  /* Infinite loop */
  for(;;)
  {
	   // osThreadTerminate(NULL);
  }
  /* USER CODE END 5 */
}

void StartLEDTask(void *argument)
{
  /* USER CODE BEGIN StartLEDTask */
  /* Infinite loop */
  for(;;)
  {
	  if(board_current.default_cfg)
	  {
		  HAL_GPIO_WritePin(LED_BLUE_GPIO_Port, LED_BLUE_Pin, 1);
	  }

	HAL_GPIO_TogglePin(LED_GREEN_GPIO_Port, LED_GREEN_Pin);
	osDelay(pdMS_TO_TICKS(500));
  }
  /* USER CODE END StartLEDTask */
}

void StartTriggerTask(void *argument)
{
  /* USER CODE BEGIN StartTriggerTask */
	uint8_t trigger_status = 0;
  /* Infinite loop */

  for(;;)
  {
	  if(osOK == osMessageQueueGet(QueueTriggerHandle, &trigger_status, NULL, 10U))
	  {
			HAL_GPIO_TogglePin(LED_RED_GPIO_Port, LED_RED_Pin);
	  }
	  osDelay(pdMS_TO_TICKS(2));
  }
  /* USER CODE END StartTriggerTask */
}

void StartMeasurTask(void *argument)
{
  /* USER CODE BEGIN StartMeasurTask */
  /* Infinite loop */
  for(;;)
  {
	  HAL_UART_Init(&huart2);
	  if(HAL_OK ==HAL_UART_Receive(&huart2, (uint8_t *)rx_data, 6, 600))
	  {
		  HAL_GPIO_TogglePin(LED_GREEN_GPIO_Port, LED_GREEN_Pin);
		  new_data = 1;
	  }
	  else
	  {
		  HAL_GPIO_TogglePin(LED_RED_GPIO_Port, LED_RED_Pin);
		  count_fail++;
	  }
	  HAL_UART_DeInit(&huart2);
	  osDelay(pdMS_TO_TICKS(5));
  }
  /* USER CODE END StartMeasurTask */
}

 /**
  * @brief  Period elapsed callback in non blocking mode
  * @note   This function is called  when TIM1 interrupt took place, inside
  * HAL_TIM_IRQHandler(). It makes a direct call to HAL_IncTick() to increment
  * a global variable "uwTick" used as application time base.
  * @param  htim : TIM handle
  * @retval None
  */
void HAL_TIM_PeriodElapsedCallback(TIM_HandleTypeDef *htim)
{
  if (htim->Instance == TIM1) {
    HAL_IncTick();
  }
}

void Error_Handler(void)
{
}

/************************ (C) COPYRIGHT STMicroelectronics *****END OF FILE****/
